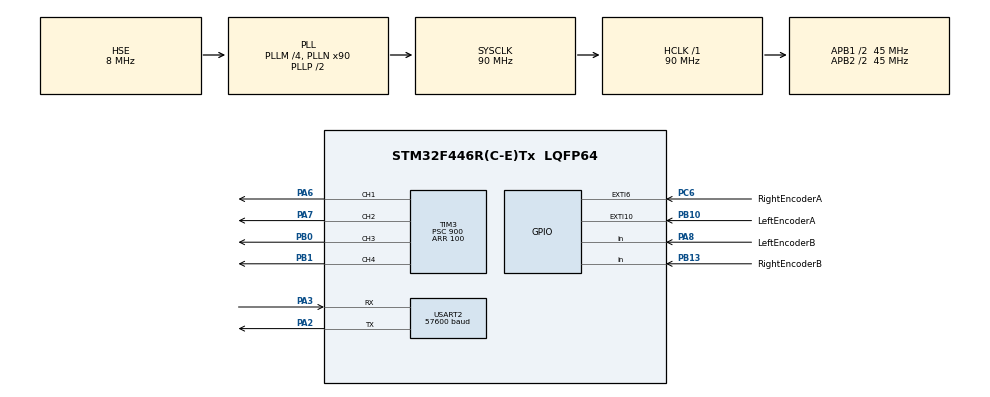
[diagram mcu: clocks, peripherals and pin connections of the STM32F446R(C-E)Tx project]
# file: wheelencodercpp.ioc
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Dma.Request0=USART2_TX
Dma.Request1=USART2_RX
Dma.USART2_RX.1.Direction=DMA_PERIPH_TO_MEMORY
Dma.USART2_RX.1.FIFOMode=DMA_FIFOMODE_DISABLE
Dma.USART2_RX.1.Instance=DMA1_Stream5
Dma.USART2_RX.1.MemDataAlignment=DMA_MDATAALIGN_BYTE
Dma.USART2_RX.1.MemInc=DMA_MINC_ENABLE
Dma.USART2_RX.1.Mode=DMA_CIRCULAR
Dma.USART2_RX.1.PeriphDataAlignment=DMA_PDATAALIGN_BYTE
Dma.USART2_RX.1.PeriphInc=DMA_PINC_DISABLE
Dma.USART2_RX.1.Priority=DMA_PRIORITY_HIGH
Dma.USART2_TX.0.Direction=DMA_MEMORY_TO_PERIPH
Dma.USART2_TX.0.FIFOMode=DMA_FIFOMODE_DISABLE
Dma.USART2_TX.0.Instance=DMA1_Stream6
Dma.USART2_TX.0.MemDataAlignment=DMA_MDATAALIGN_BYTE
Dma.USART2_TX.0.MemInc=DMA_MINC_ENABLE
Dma.USART2_TX.0.Mode=DMA_NORMAL
Dma.USART2_TX.0.PeriphDataAlignment=DMA_PDATAALIGN_BYTE
Dma.USART2_TX.0.PeriphInc=DMA_PINC_DISABLE
Dma.USART2_TX.0.Priority=DMA_PRIORITY_HIGH
Mcu.Family=STM32F4
Mcu.Name=STM32F446R(C-E)Tx
Mcu.Package=LQFP64
NVIC.DMA1_Stream5_IRQn=true\:0\:0\:false\:false\:true\:false\:true\:true
NVIC.DMA1_Stream6_IRQn=true\:0\:0\:false\:false\:true\:false\:true\:true
NVIC.EXTI15_10_IRQn=true\:0\:0\:false\:false\:true\:true\:true\:true
NVIC.EXTI9_5_IRQn=true\:0\:0\:false\:false\:true\:true\:true\:true
NVIC.PriorityGroup=NVIC_PRIORITYGROUP_0
NVIC.TIM2_IRQn=true\:0\:0\:false\:false\:true\:true\:true\:true
NVIC.USART2_IRQn=true\:0\:0\:false\:false\:true\:true\:true\:true
PA13.Mode=Serial_Wire
PA13.Signal=SYS_JTMS-SWDIO
PA14.Mode=Serial_Wire
PA14.Signal=SYS_JTCK-SWCLK
PA2.Mode=Asynchronous
PA2.Signal=USART2_TX
PA3.Mode=Asynchronous
PA3.Signal=USART2_RX
PA6.Signal=S_TIM3_CH1
PA7.Signal=S_TIM3_CH2
PA8.GPIO_Label=LeftEncoderB
PA8.GPIO_PuPd=GPIO_PULLUP
PA8.Signal=GPIO_Input
PB0.Signal=S_TIM3_CH3
PB1.Signal=S_TIM3_CH4
PB10.GPIO_Label=LeftEncoderA
PB10.GPIO_ModeDefaultEXTI=GPIO_MODE_IT_RISING_FALLING
PB10.GPIO_PuPd=GPIO_PULLUP
PB10.Signal=GPXTI10
PB13.GPIO_Label=RightEncoderB
PB13.GPIO_PuPd=GPIO_PULLUP
PB13.Signal=GPIO_Input
PC6.GPIO_Label=RightEncoderA
PC6.GPIO_ModeDefaultEXTI=GPIO_MODE_IT_RISING_FALLING
PC6.GPIO_PuPd=GPIO_PULLUP
PC6.Signal=GPXTI6
PH0-OSC_IN.Mode=HSE-External-Oscillator
PH0-OSC_IN.Signal=RCC_OSC_IN
PH1-OSC_OUT.Mode=HSE-External-Oscillator
PH1-OSC_OUT.Signal=RCC_OSC_OUT
ProjectManager.HeapSize=0x200
ProjectManager.StackSize=0x400
ProjectManager.TargetToolchain=STM32CubeIDE
RCC.48MHZClocksFreq_Value=84000000
RCC.AHBFreq_Value=90000000
RCC.APB1CLKDivider=RCC_HCLK_DIV2
RCC.APB1Freq_Value=45000000
RCC.APB1TimFreq_Value=90000000
RCC.APB2CLKDivider=RCC_HCLK_DIV2
RCC.APB2Freq_Value=45000000
RCC.APB2TimFreq_Value=90000000
RCC.CortexFreq_Value=90000000
RCC.FLatency-AdvancedSettings=FLASH_LATENCY_2
RCC.HCLKFreq_Value=90000000
RCC.HSE_VALUE=8000000
RCC.HSI_VALUE=16000000
RCC.PLLM=4
RCC.PLLN=90
RCC.PLLSourceVirtual=RCC_PLLSOURCE_HSE
RCC.SYSCLKFreq_VALUE=90000000
RCC.SYSCLKSource=RCC_SYSCLKSOURCE_PLLCLK
RCC.USBFreq_Value=90000000
RCC.VCOOutputFreq_Value=180000000
SH.S_TIM3_CH1.0=TIM3_CH1,PWM Generation1 CH1
SH.S_TIM3_CH2.0=TIM3_CH2,PWM Generation2 CH2
SH.S_TIM3_CH3.0=TIM3_CH3,PWM Generation3 CH3
SH.S_TIM3_CH4.0=TIM3_CH4,PWM Generation4 CH4
TIM2.Period=150
TIM2.Prescaler=60000
TIM3.Channel-PWM\ Generation1\ CH1=TIM_CHANNEL_1
TIM3.Channel-PWM\ Generation2\ CH2=TIM_CHANNEL_2
TIM3.Channel-PWM\ Generation3\ CH3=TIM_CHANNEL_3
TIM3.Channel-PWM\ Generation4\ CH4=TIM_CHANNEL_4
TIM3.Period=100
TIM3.Prescaler=900
TIM3.Pulse-PWM\ Generation1\ CH1=50
USART2.BaudRate=57600
USART2.VirtualMode=VM_ASYNC
VP_TIM2_VS_ClockSourceINT.Mode=Internal
VP_TIM3_VS_ClockSourceINT.Mode=Internal
board=NUCLEO-F446RE

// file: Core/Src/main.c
/* USER CODE BEGIN Header */
/**
  ******************************************************************************
  * @file           : main.c
  * @brief          : Main program body
  ******************************************************************************
  * @attention
  *
  * Copyright (c) 2023 STMicroelectronics.
  * All rights reserved.
  *
  * This software is licensed under terms that can be found in the LICENSE file
  * in the root directory of this software component.
  * If no LICENSE file comes with this software, it is provided AS-IS.
  *
  ******************************************************************************
  */
/* USER CODE END Header */
#include "main.h"

/* USER CODE BEGIN Includes */
#include <stdio.h>
#include <mainpp.h>
/* USER CODE END Includes */

TIM_HandleTypeDef htim2;
TIM_HandleTypeDef htim3;

UART_HandleTypeDef huart2;
DMA_HandleTypeDef hdma_usart2_tx;
DMA_HandleTypeDef hdma_usart2_rx;

void SystemClock_Config(void);
static void MX_GPIO_Init(void);
static void MX_DMA_Init(void);
static void MX_USART2_UART_Init(void);
static void MX_TIM2_Init(void);
static void MX_TIM3_Init(void);

/* USER CODE BEGIN 0 */

/*
void HAL_TIM_PeriodElapsedCallback(TIM_HandleTypeDef *htim)
{

	rpm = (int)((rightenc - rightenco)*0.6); //(No. of ticks Now - No. of Ticks Old)*60/(50*10^-3) (old calc)
	rightvel = (int)((rpm * 6.28 * 7.5)/(60));
	rightenco = rightenc;
	HAL_GPIO_TogglePin(GPIOA, GPIO_PIN_5);

}*/
/* USER CODE END 0 */

int main(void)
{

  /* MCU Configuration--------------------------------------------------------*/

  /* Reset of all peripherals, Initializes the Flash interface and the Systick. */
  HAL_Init();

  /* Configure the system clock */
  SystemClock_Config();

  /* Initialize all configured peripherals */
  MX_GPIO_Init();
  MX_DMA_Init();
  MX_USART2_UART_Init();
  MX_TIM2_Init();
  MX_TIM3_Init();
  /* USER CODE BEGIN 2 */
  HAL_TIM_Base_Start(&htim3);
  HAL_TIM_PWM_Start(&htim3, TIM_CHANNEL_1);
  HAL_TIM_PWM_Start(&htim3, TIM_CHANNEL_2);
  HAL_TIM_PWM_Start(&htim3, TIM_CHANNEL_3);
  HAL_TIM_PWM_Start(&htim3, TIM_CHANNEL_4);
  HAL_TIM_Base_Start_IT(&htim2);
  setup();

    /*char uart_buf[100];//lingesh is gae
    int uart_buf_len;*/
  /* USER CODE END 2 */

  /* Infinite loop */
  /* USER CODE BEGIN WHILE */
  while (1)
  {
	  loop();
    /* USER CODE END WHILE */

  }
}

void SystemClock_Config(void)
{
  RCC_OscInitTypeDef RCC_OscInitStruct = {0};
  RCC_ClkInitTypeDef RCC_ClkInitStruct = {0};

  /** Configure the main internal regulator output voltage
  */
  __HAL_RCC_PWR_CLK_ENABLE();
  __HAL_PWR_VOLTAGESCALING_CONFIG(PWR_REGULATOR_VOLTAGE_SCALE3);

  /** Initializes the RCC Oscillators according to the specified parameters
  * in the RCC_OscInitTypeDef structure.
  */
  RCC_OscInitStruct.OscillatorType = RCC_OSCILLATORTYPE_HSE;
  RCC_OscInitStruct.HSEState = RCC_HSE_ON;
  RCC_OscInitStruct.PLL.PLLState = RCC_PLL_ON;
  RCC_OscInitStruct.PLL.PLLSource = RCC_PLLSOURCE_HSE;
  RCC_OscInitStruct.PLL.PLLM = 4;
  RCC_OscInitStruct.PLL.PLLN = 90;
  RCC_OscInitStruct.PLL.PLLP = RCC_PLLP_DIV2;
  RCC_OscInitStruct.PLL.PLLQ = 2;
  RCC_OscInitStruct.PLL.PLLR = 2;
  if (HAL_RCC_OscConfig(&RCC_OscInitStruct) != HAL_OK)
  {
    Error_Handler();
  }

  /** Initializes the CPU, AHB and APB buses clocks
  */
  RCC_ClkInitStruct.ClockType = RCC_CLOCKTYPE_HCLK|RCC_CLOCKTYPE_SYSCLK
                              |RCC_CLOCKTYPE_PCLK1|RCC_CLOCKTYPE_PCLK2;
  RCC_ClkInitStruct.SYSCLKSource = RCC_SYSCLKSOURCE_PLLCLK;
  RCC_ClkInitStruct.AHBCLKDivider = RCC_SYSCLK_DIV1;
  RCC_ClkInitStruct.APB1CLKDivider = RCC_HCLK_DIV2;
  RCC_ClkInitStruct.APB2CLKDivider = RCC_HCLK_DIV2;

  if (HAL_RCC_ClockConfig(&RCC_ClkInitStruct, FLASH_LATENCY_2) != HAL_OK)
  {
    Error_Handler();
  }
}

static void MX_TIM2_Init(void)
{

  TIM_ClockConfigTypeDef sClockSourceConfig = {0};
  TIM_MasterConfigTypeDef sMasterConfig = {0};

  htim2.Instance = TIM2;
  htim2.Init.Prescaler = 60000;
  htim2.Init.CounterMode = TIM_COUNTERMODE_UP;
  htim2.Init.Period = 150;
  htim2.Init.ClockDivision = TIM_CLOCKDIVISION_DIV1;
  htim2.Init.AutoReloadPreload = TIM_AUTORELOAD_PRELOAD_DISABLE;
  if (HAL_TIM_Base_Init(&htim2) != HAL_OK)
  {
    Error_Handler();
  }
  sClockSourceConfig.ClockSource = TIM_CLOCKSOURCE_INTERNAL;
  if (HAL_TIM_ConfigClockSource(&htim2, &sClockSourceConfig) != HAL_OK)
  {
    Error_Handler();
  }
  sMasterConfig.MasterOutputTrigger = TIM_TRGO_RESET;
  sMasterConfig.MasterSlaveMode = TIM_MASTERSLAVEMODE_DISABLE;
  if (HAL_TIMEx_MasterConfigSynchronization(&htim2, &sMasterConfig) != HAL_OK)
  {
    Error_Handler();
  }

}

static void MX_TIM3_Init(void)
{

  TIM_ClockConfigTypeDef sClockSourceConfig = {0};
  TIM_MasterConfigTypeDef sMasterConfig = {0};
  TIM_OC_InitTypeDef sConfigOC = {0};

  htim3.Instance = TIM3;
  htim3.Init.Prescaler = 900;
  htim3.Init.CounterMode = TIM_COUNTERMODE_UP;
  htim3.Init.Period = 100;
  htim3.Init.ClockDivision = TIM_CLOCKDIVISION_DIV1;
  htim3.Init.AutoReloadPreload = TIM_AUTORELOAD_PRELOAD_DISABLE;
  if (HAL_TIM_Base_Init(&htim3) != HAL_OK)
  {
    Error_Handler();
  }
  sClockSourceConfig.ClockSource = TIM_CLOCKSOURCE_INTERNAL;
  if (HAL_TIM_ConfigClockSource(&htim3, &sClockSourceConfig) != HAL_OK)
  {
    Error_Handler();
  }
  if (HAL_TIM_PWM_Init(&htim3) != HAL_OK)
  {
    Error_Handler();
  }
  sMasterConfig.MasterOutputTrigger = TIM_TRGO_RESET;
  sMasterConfig.MasterSlaveMode = TIM_MASTERSLAVEMODE_DISABLE;
  if (HAL_TIMEx_MasterConfigSynchronization(&htim3, &sMasterConfig) != HAL_OK)
  {
    Error_Handler();
  }
  sConfigOC.OCMode = TIM_OCMODE_PWM1;
  sConfigOC.Pulse = 50;
  sConfigOC.OCPolarity = TIM_OCPOLARITY_HIGH;
  sConfigOC.OCFastMode = TIM_OCFAST_DISABLE;
  if (HAL_TIM_PWM_ConfigChannel(&htim3, &sConfigOC, TIM_CHANNEL_1) != HAL_OK)
  {
    Error_Handler();
  }
  sConfigOC.Pulse = 0;
  if (HAL_TIM_PWM_ConfigChannel(&htim3, &sConfigOC, TIM_CHANNEL_2) != HAL_OK)
  {
    Error_Handler();
  }
  if (HAL_TIM_PWM_ConfigChannel(&htim3, &sConfigOC, TIM_CHANNEL_3) != HAL_OK)
  {
    Error_Handler();
  }
  if (HAL_TIM_PWM_ConfigChannel(&htim3, &sConfigOC, TIM_CHANNEL_4) != HAL_OK)
  {
    Error_Handler();
  }
  HAL_TIM_MspPostInit(&htim3);

}

static void MX_USART2_UART_Init(void)
{

  huart2.Instance = USART2;
  huart2.Init.BaudRate = 57600;
  huart2.Init.WordLength = UART_WORDLENGTH_8B;
  huart2.Init.StopBits = UART_STOPBITS_1;
  huart2.Init.Parity = UART_PARITY_NONE;
  huart2.Init.Mode = UART_MODE_TX_RX;
  huart2.Init.HwFlowCtl = UART_HWCONTROL_NONE;
  huart2.Init.OverSampling = UART_OVERSAMPLING_16;
  if (HAL_UART_Init(&huart2) != HAL_OK)
  {
    Error_Handler();
  }

}

static void MX_DMA_Init(void)
{

  /* DMA controller clock enable */
  __HAL_RCC_DMA1_CLK_ENABLE();

  /* DMA interrupt init */
  /* DMA1_Stream5_IRQn interrupt configuration */
  HAL_NVIC_SetPriority(DMA1_Stream5_IRQn, 0, 0);
  HAL_NVIC_EnableIRQ(DMA1_Stream5_IRQn);
  /* DMA1_Stream6_IRQn interrupt configuration */
  HAL_NVIC_SetPriority(DMA1_Stream6_IRQn, 0, 0);
  HAL_NVIC_EnableIRQ(DMA1_Stream6_IRQn);

}

static void MX_GPIO_Init(void)
{
  GPIO_InitTypeDef GPIO_InitStruct = {0};

  /* GPIO Ports Clock Enable */
  __HAL_RCC_GPIOH_CLK_ENABLE();
  __HAL_RCC_GPIOA_CLK_ENABLE();
  __HAL_RCC_GPIOB_CLK_ENABLE();
  __HAL_RCC_GPIOC_CLK_ENABLE();

  /*Configure GPIO pin : LeftEncoderA_Pin */
  GPIO_InitStruct.Pin = LeftEncoderA_Pin;
  GPIO_InitStruct.Mode = GPIO_MODE_IT_RISING_FALLING;
  GPIO_InitStruct.Pull = GPIO_PULLUP;
  HAL_GPIO_Init(LeftEncoderA_GPIO_Port, &GPIO_InitStruct);

  /*Configure GPIO pin : RightEncoderB_Pin */
  GPIO_InitStruct.Pin = RightEncoderB_Pin;
  GPIO_InitStruct.Mode = GPIO_MODE_INPUT;
  GPIO_InitStruct.Pull = GPIO_PULLUP;
  HAL_GPIO_Init(RightEncoderB_GPIO_Port, &GPIO_InitStruct);

  /*Configure GPIO pin : RightEncoderA_Pin */
  GPIO_InitStruct.Pin = RightEncoderA_Pin;
  GPIO_InitStruct.Mode = GPIO_MODE_IT_RISING_FALLING;
  GPIO_InitStruct.Pull = GPIO_PULLUP;
  HAL_GPIO_Init(RightEncoderA_GPIO_Port, &GPIO_InitStruct);

  /*Configure GPIO pin : LeftEncoderB_Pin */
  GPIO_InitStruct.Pin = LeftEncoderB_Pin;
  GPIO_InitStruct.Mode = GPIO_MODE_INPUT;
  GPIO_InitStruct.Pull = GPIO_PULLUP;
  HAL_GPIO_Init(LeftEncoderB_GPIO_Port, &GPIO_InitStruct);

  /* EXTI interrupt init*/
  HAL_NVIC_SetPriority(EXTI9_5_IRQn, 0, 0);
  HAL_NVIC_EnableIRQ(EXTI9_5_IRQn);

  HAL_NVIC_SetPriority(EXTI15_10_IRQn, 0, 0);
  HAL_NVIC_EnableIRQ(EXTI15_10_IRQn);

}

void Error_Handler(void)
{
  __disable_irq();
  while (1)
  {
  }
}
